# MAX32600 register map
File version: 1.0
Registers are 32-bit, read-write, reset 0x0 unless marked. A register's access mark holds for its fields unless they carry their own. Offsets are from the block's base; [hi:lo] are bit positions.

## PWRSEQ — Power Sequencer
Base 0x40090A30
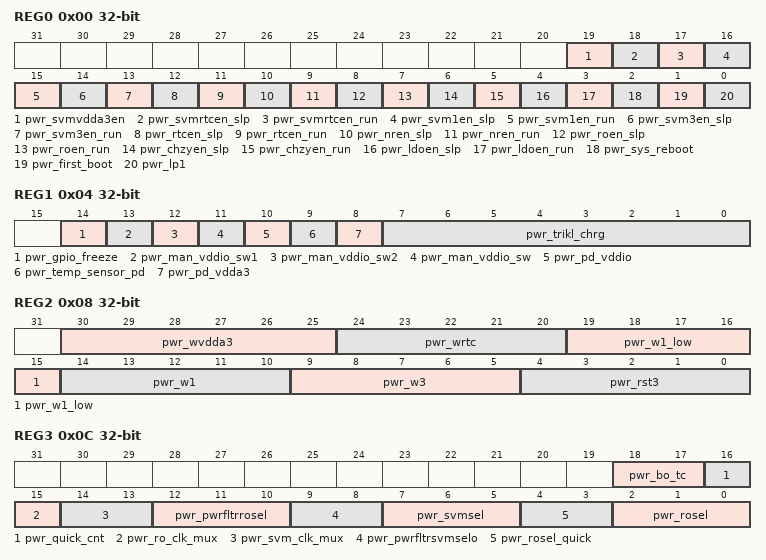
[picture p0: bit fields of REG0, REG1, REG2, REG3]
0x00 REG0 — Power Sequencer Control Register 0
  [19] pwr_svmvdda3en — Enable VDDA3 SVM operation (in Run Mode only)
  [18] pwr_svmrtcen_slp — Enable VRTC SVM operation in Sleep Mode
  [17] pwr_svmrtcen_run — Enable VRTC SVM operation in Run Mode
  [16] pwr_svm1en_slp — Enable VREG18 SVM operation in Sleep Mode
  [15] pwr_svm1en_run — Enable VREG18 SVM operation in Run Mode
  [14] pwr_svm3en_slp — Enable VDD3 SVM operation in Sleep Mode
  [13] pwr_svm3en_run — Enable VDD3 SVM operation in Run Mode
  [12] pwr_rtcen_slp — Enable Real Time Clock operation in Sleep Mode
  [11] pwr_rtcen_run — Enable Real Time Clock operation in Run Mode
  [10] pwr_nren_slp — Enable Nano Oscillator in Sleep Mode
  [9] pwr_nren_run — Enable Nano Oscillator in Run Mode
  [8] pwr_roen_slp — Enable System Relaxation Oscillator in Sleep Mode
  [7] pwr_roen_run — Enable System Relaxation Oscillator in Run Mode
  [6] pwr_chzyen_slp — Enable Backup 1.8V LDO Operation in Sleep Mode
  [5] pwr_chzyen_run — Enable Backup 1.8V LDO Operation in Run Mode
  [4] pwr_ldoen_slp — Enable Main 1.8V LDO Operation in Sleep Mode
  [3] pwr_ldoen_run — Enable Main 1.8V LDO Operation in Run Mode
  [2] pwr_sys_reboot wo — Firmware System Reboot Request
  [1] pwr_first_boot — Wake on First Boot
  [0] pwr_lp1 — Shutdown Power Mode Select
0x04 REG1 — Power Sequencer Control Register 1
  [14] pwr_gpio_freeze — Freeze GPIO WUD and Keeper Latches
  [13] pwr_man_vddio_sw1 — Manual Override for VDDIO_SW1
  [12] pwr_man_vddio_sw2 — Manual Override for VDDIO_SW2
  [11] pwr_man_vddio_sw — Manual Override Enable for VDDIO Switch 1/2
  [10] pwr_pd_vddio — Power Down VDDIO Supply Rail
  [9] pwr_temp_sensor_pd — Power Down Internal Temperature Sensor
  [8] pwr_pd_vdda3 — Power Down VDDA3 Supply Rail
  [7:0] pwr_trikl_chrg — Trickle Charge Control for VRTC External Capacitor
0x08 REG2 — Power Sequencer Control Register 2
  [30:25] pwr_wvdda3 — pwr_wvdda3_o[5:0]
  [24:20] pwr_wrtc — pwr_wrtc_o[4:0]
  [19:15] pwr_w1_low — pwr_w1_low_o[4:0]
  [14:10] pwr_w1 — pwr_w1_o[4:0]
  [9:5] pwr_w3 — pwr_w3_o[4:0]
  [4:0] pwr_rst3 — pwr_rst3_o - VDD3 Reset decode
0x0C REG3 — Power Sequencer Control Register 3
  [18:17] pwr_bo_tc — Brownout Detection Time Constant
  [16] pwr_quick_cnt — pwr_quick_cnt_o
  [15] pwr_ro_clk_mux — pwr_ro_clk_mux_o
  [14:13] pwr_svm_clk_mux — pwr_svm_clk_mux_o[1:0]
  [12:10] pwr_pwrfltrrosel — pwr_pwrfltrrosel_o[2:0]
  [9:8] pwr_pwrfltrsvmselo — pwr_pwrfltrsvmselo_o[1:0]
  [7:5] pwr_svmsel — pwr_svmsel_o[2:0]
  [4:3] pwr_rosel_quick — pwr_rosel_quick_o[1:0]
  [2:0] pwr_rosel — pwr_rosel_o[2:0]
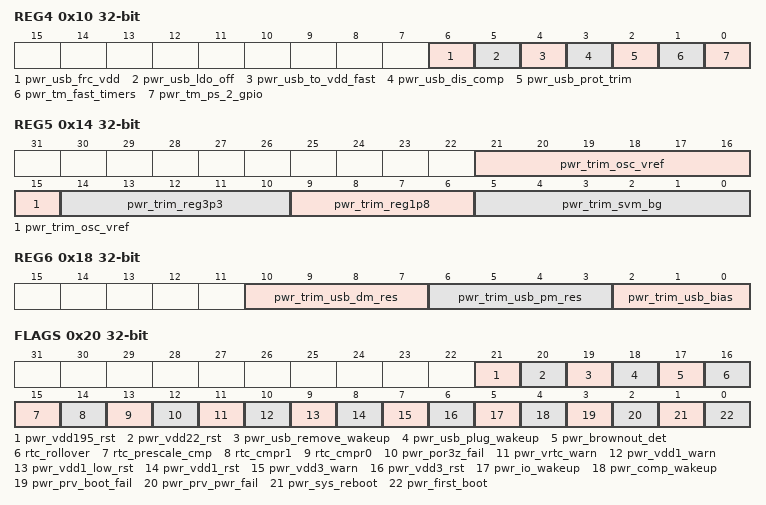
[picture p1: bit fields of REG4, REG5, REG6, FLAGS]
0x10 REG4 — Power Sequencer Control Register 4
  [6] pwr_usb_frc_vdd — pwr_usbFrcVdd_w
  [5] pwr_usb_ldo_off — pwr_usbLdoOff_w
  [4] pwr_usb_to_vdd_fast — pwr_usbToVddFast_w
  [3] pwr_usb_dis_comp — pwr_usb_dis_comp_o
  [2] pwr_usb_prot_trim — pwr_usb_prot_trim_o
  [1] pwr_tm_fast_timers — pwr_tm_fast_timers_o
  [0] pwr_tm_ps_2_gpio — pwr_tm_ps_2_gpio_w
0x14 REG5 — Power Sequencer Control Register 5 (Trim 0)
  [21:15] pwr_trim_osc_vref — pwr_trim_osc_vref_o[6:0]
  [14:10] pwr_trim_reg3p3 — pwr_trim_reg3p3_o[4:0]
  [9:6] pwr_trim_reg1p8 — pwr_trim_reg1p8_w[3:0]
  [5:0] pwr_trim_svm_bg — pwr_trim_svm_bg_w[5:0]
0x18 REG6 — Power Sequencer Control Register 6 (Trim 1)
  [10:7] pwr_trim_usb_dm_res — pwr_trim_usb_dm_res_o[3:0]
  [6:3] pwr_trim_usb_pm_res — pwr_trim_usb_pm_res_o[3:0]
  [2:0] pwr_trim_usb_bias — pwr_trim_usb_bias_o[2:0]
0x20 FLAGS — Power Sequencer Flags
  [21] pwr_vdd195_rst write-1-clears
  [20] pwr_vdd22_rst write-1-clears
  [19] pwr_usb_remove_wakeup write-1-clears — pwr_usb_remove_wakeup_detected
  [18] pwr_usb_plug_wakeup write-1-clears — pwr_usb_plug_wakeup_detected
  [17] pwr_brownout_det write-1-clears — pwr_brownout_detected
  [16] rtc_rollover write-1-clears — rtc_rollover_flag
  [15] rtc_prescale_cmp write-1-clears — rtc_prescale_cmp_flag
  [14] rtc_cmpr1 write-1-clears — rtc_cmpr1_flag
  [13] rtc_cmpr0 write-1-clears — rtc_cmpr0_flag
  [12] pwr_por3z_fail write-1-clears — pwr_por3z_fail_latch_r
  [11] pwr_vrtc_warn write-1-clears — pwr_vrtc_warn_bad_r
  [10] pwr_vdd1_warn write-1-clears — pwr_vdd1_warn_bad_r
  [9] pwr_vdd1_low_rst write-1-clears — pwr_vdd1_low_rst_bad_r
  [8] pwr_vdd1_rst write-1-clears — pwr_vdd1_rst_bad_r
  [7] pwr_vdd3_warn write-1-clears — pwr_vdd3_warn_bad_r
  [6] pwr_vdd3_rst write-1-clears — pwr_vdd3_rst_bad_r
  [5] pwr_io_wakeup write-1-clears — pwr_iowakeup_latch_r
  [4] pwr_comp_wakeup write-1-clears — pwr_comp_wakeup_latch_r
  [3] pwr_prv_boot_fail write-1-clears — pwr_prv_boot_fail_r
  [2] pwr_prv_pwr_fail write-1-clears — pwr_prv_pwr_fail_r
  [1] pwr_sys_reboot ro — pwr_sys_reboot_o
  [0] pwr_first_boot ro — pwr_first_boot_o
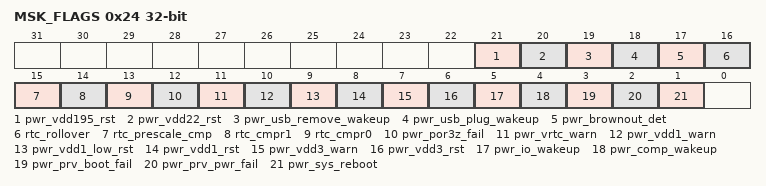
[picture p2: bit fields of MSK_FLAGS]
0x24 MSK_FLAGS — Power Sequencer Flags Mask Register
  [21] pwr_vdd195_rst — Mask for VDD195 reset event
  [20] pwr_vdd22_rst — Mask for VDD22 reset event
  [19] pwr_usb_remove_wakeup — Mask for USB power disconnected wakeup event
  [18] pwr_usb_plug_wakeup — Mask for USB power connected wakeup event
  [17] pwr_brownout_det — Mask for power brownout detect
  [16] rtc_rollover — Mask for RTC rollover event
  [15] rtc_prescale_cmp — Mask for RTC prescale compare event
  [14] rtc_cmpr1 — Mask for RTC compare 1 event
  [13] rtc_cmpr0 — Mask for RTC compare 0 event
  [12] pwr_por3z_fail — Mask for POR3Z supply fail event detect
  [11] pwr_vrtc_warn — Mask for VRTC power fail detect
  [10] pwr_vdd1_warn — Mask for VREG18 warning level event detect
  [9] pwr_vdd1_low_rst — Mask for VREG18 reset LOW compare event
  [8] pwr_vdd1_rst — Mask for VREG18 reset compare event detect
  [7] pwr_vdd3_warn — Mask for VDD3 voltage warning event detect
  [6] pwr_vdd3_rst — Mask for VDD3 reset comparator event detect
  [5] pwr_io_wakeup — Mask for GPIO wakeup event detect
  [4] pwr_comp_wakeup — Mask for analog comparator wakeup detect
  [3] pwr_prv_boot_fail — Mask for previous boot fail detect
  [2] pwr_prv_pwr_fail — Mask for previous power fail detect
  [1] pwr_sys_reboot — Mask for system reboot detect
